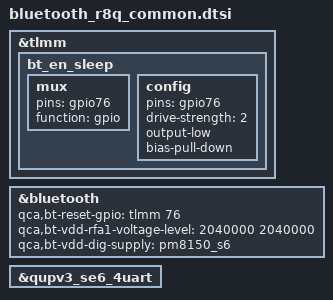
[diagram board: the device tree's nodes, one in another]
/* Copyright (c) 2019, The Linux Foundation. All rights reserved.
 *
 * This program is free software; you can redistribute it and/or modify
 * it under the terms of the GNU General Public License version 2 and
 * only version 2 as published by the Free Software Foundation.
 *
 * This program is distributed in the hope that it will be useful,
 * but WITHOUT ANY WARRANTY; without even the implied warranty of
 * MERCHANTABILITY or FITNESS FOR A PARTICULAR PURPOSE.  See the
 * GNU General Public License for more details.
 */

&tlmm {
	bt_en_sleep: bt_en_sleep{
		mux {
			pins = "gpio76";
			function = "gpio";
		};
		config {
			pins = "gpio76";
			drive-strength = <2>;
			output-low;
			bias-pull-down;
		};
	};
};

&bluetooth {
	qca,bt-reset-gpio = <&tlmm 76 0>; /* BT_EN */
	qca,bt-vdd-rfa1-voltage-level = <2040000 2040000>;
	qca,bt-vdd-dig-supply = <&pm8150_s6>;
	/delete-property/ qca,bt-vdd-asd-supply;
	/delete-property/ qca,bt-vdd-asd-voltage-level;
	status = "ok";
};

&qupv3_se6_4uart {
	status = "ok";
};
